AUTOSAR XML (schema 4-0-3)
package /ComponentTypes
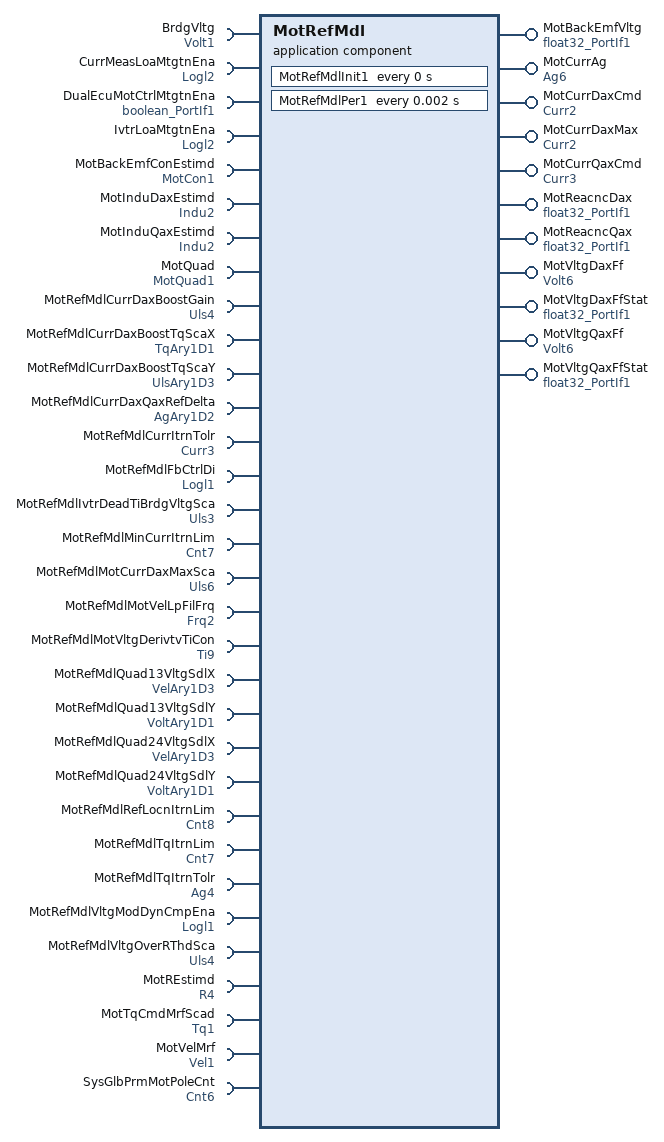
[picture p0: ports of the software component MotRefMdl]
  application sw component type MotRefMdl
    11 x provide port, all with nonqueued-sender-com-spec{data-element=Val, init-value=0}:
      MotBackEmfVltg: provided-interface=float32_PortIf1
      MotCurrAg: provided-interface=Ag6
      MotCurrDaxCmd: provided-interface=Curr2
      MotCurrDaxMax: provided-interface=Curr2
      MotCurrQaxCmd: provided-interface=Curr3
      MotReacncDax: provided-interface=float32_PortIf1
      MotReacncQax: provided-interface=float32_PortIf1
      MotVltgDaxFf: provided-interface=Volt6
      MotVltgDaxFfStat: provided-interface=float32_PortIf1
      MotVltgQaxFf: provided-interface=Volt6
      MotVltgQaxFfStat: provided-interface=float32_PortIf1
    32 x require port:
      BrdgVltg: nonqueued-receiver-com-spec{data-element=Val, filter=data-filter-type=ALWAYS, init-value=6}, required-interface=Volt1
      CurrMeasLoaMtgtnEna: nonqueued-receiver-com-spec{data-element=Logl, filter=data-filter-type=ALWAYS, init-value=0}, required-interface=Logl2
      DualEcuMotCtrlMtgtnEna: nonqueued-receiver-com-spec{data-element=Logl, filter=data-filter-type=ALWAYS, init-value=0}, required-interface=boolean_PortIf1
      IvtrLoaMtgtnEna: nonqueued-receiver-com-spec{data-element=Logl, filter=data-filter-type=ALWAYS, init-value=0}, required-interface=Logl2
      MotBackEmfConEstimd: nonqueued-receiver-com-spec{data-element=Val, filter=data-filter-type=ALWAYS, init-value=0.025}, required-interface=MotCon1
      MotInduDaxEstimd: nonqueued-receiver-com-spec{data-element=Val, filter=data-filter-type=ALWAYS, init-value=0.00011889}, required-interface=Indu2
      MotInduQaxEstimd: nonqueued-receiver-com-spec{data-element=Val, filter=data-filter-type=ALWAYS, init-value=0.00011889}, required-interface=Indu2
      MotQuad: nonqueued-receiver-com-spec{data-element=Val, filter=data-filter-type=ALWAYS, init-value=1}, required-interface=MotQuad1
      MotRefMdlCurrDaxBoostGain: parameter-require-com-spec{init-value=0, parameter=Val}, required-interface=Uls4
      MotRefMdlCurrDaxBoostTqScaX: parameter-require-com-spec{init-value=[0, 1.5, 1.75, 2, 2.25, 2.5, 3, 3.5, 4, 4.5, 5], parameter=Ary1D}, required-interface=TqAry1D1
      MotRefMdlCurrDaxBoostTqScaY: parameter-require-com-spec{init-value=[0, 0.5, 0.6, 0.7, 0.725, 0.775, 0.825, 0.85, 0.9, 0.95, 1], parameter=Ary1D}, required-interface=UlsAry1D3
      MotRefMdlCurrDaxQaxRefDelta: parameter-require-com-spec{init-value=[-3.1415927, -2.3561945, -1.5707964, -0.7853982, 0, 0.7853982, 1.5707964, 2.3561945], parameter=Ary1D}, required-interface=AgAry1D2
      MotRefMdlCurrItrnTolr: parameter-require-com-spec{init-value=0.1, parameter=Val}, required-interface=Curr3
      MotRefMdlFbCtrlDi: parameter-require-com-spec{init-value=0, parameter=Logl}, required-interface=Logl1
      MotRefMdlIvtrDeadTiBrdgVltgSca: parameter-require-com-spec{init-value=1, parameter=Val}, required-interface=Uls3
      MotRefMdlMinCurrItrnLim: parameter-require-com-spec{init-value=3, parameter=Val}, required-interface=Cnt7
      MotRefMdlMotCurrDaxMaxSca: parameter-require-com-spec{init-value=1, parameter=Val}, required-interface=Uls6
      MotRefMdlMotVelLpFilFrq: parameter-require-com-spec{init-value=125, parameter=Val}, required-interface=Frq2
      MotRefMdlMotVltgDerivtvTiCon: parameter-require-com-spec{init-value=0.0026526, parameter=Val}, required-interface=Ti9
      MotRefMdlQuad13VltgSdlX: parameter-require-com-spec{init-value=[0, 100, 200, 300, 500, 600, 700, 800, 900, 1100], parameter=Ary1D}, required-interface=VelAry1D3
      MotRefMdlQuad13VltgSdlY: parameter-require-com-spec{init-value=10 x 0, parameter=Ary1D}, required-interface=VoltAry1D1
      MotRefMdlQuad24VltgSdlX: parameter-require-com-spec{init-value=[0, 100, 200, 300, 500, 600, 700, 800, 900, 1100], parameter=Ary1D}, required-interface=VelAry1D3
      MotRefMdlQuad24VltgSdlY: parameter-require-com-spec{init-value=10 x 0, parameter=Ary1D}, required-interface=VoltAry1D1
      MotRefMdlRefLocnItrnLim: parameter-require-com-spec{init-value=10, parameter=Val}, required-interface=Cnt8
      MotRefMdlTqItrnLim: parameter-require-com-spec{init-value=3, parameter=Val}, required-interface=Cnt7
      MotRefMdlTqItrnTolr: parameter-require-com-spec{init-value=0.015, parameter=Val}, required-interface=Ag4
      MotRefMdlVltgModDynCmpEna: parameter-require-com-spec{init-value=0, parameter=Logl}, required-interface=Logl1
      MotRefMdlVltgOverRThdSca: parameter-require-com-spec{init-value=.25, parameter=Val}, required-interface=Uls4
      MotREstimd: nonqueued-receiver-com-spec{data-element=Val, filter=data-filter-type=ALWAYS, init-value=0.005}, required-interface=R4
      MotTqCmdMrfScad: nonqueued-receiver-com-spec{data-element=Val, filter=data-filter-type=ALWAYS, init-value=0}, required-interface=Tq1
      MotVelMrf: nonqueued-receiver-com-spec{data-element=Val, filter=data-filter-type=ALWAYS, init-value=0}, required-interface=Vel1
      SysGlbPrmMotPoleCnt: parameter-require-com-spec{init-value=6, parameter=Val}, required-interface=Cnt6
    behavior MotRefMdl_InternalBehavior: data-type-mapping=Nexteer
      ar-typed-per-instance-memorys:
        28 x data, all with sw-calibration-access=READ-ONLY:
          CosDelta: type=UlsAry1D6
          dMotRefMdlCurrDaxAtPeakTq: type=Curr6
          dMotRefMdlCurrDaxMin: type=Curr6
          dMotRefMdlCurrQaxMin: type=Curr7
          dMotRefMdlCurrSqdMin: type=CurrSqd1
          dMotRefMdlInterCalcnCurrDaxMax: type=Curr6
          dMotRefMdlMinCurrNrItrn: type=Cnt19
          dMotRefMdlMotCurrDaxBoost: type=Curr6
          dMotRefMdlMotTqCmdLimd: type=Tq1
          dMotRefMdlMotVelFildFf: type=Vel1
          dMotRefMdlMotVltgDaxFfDyn: type=Volt17
          dMotRefMdlMotVltgDaxFfDynTerm: type=Volt17
          dMotRefMdlMotVltgDaxFfStat: type=float32
          dMotRefMdlMotVltgQaxFfDyn: type=Volt17
          dMotRefMdlMotVltgQaxFfDynTerm: type=Volt17
          dMotRefMdlMotVltgQaxFfStat: type=float32
          dMotRefMdlPeakTq: type=Tq1
          dMotRefMdlPeakTqNrItrn: type=Cnt19
          dMotRefMdlPhaAdvAtPeakTq: type=Ag10
          dMotRefMdlReacncDaxOverR: type=Uls13
          dMotRefMdlReacncQaxOverR: type=Uls13
          dMotRefMdlRelncTqCoeff: type=Indu2
          MotCurrDaxCmdPrev: type=Curr6
          MotCurrQaxCmdPrev: type=Curr7
          MotVelLpFil: type=FilLpRec1
          SinDelta: type=UlsAry1D6
          VltgDaxFfTermPrev: type=Volt17
          VltgQaxFfTermPrev: type=Volt17
      timing event MotRefMdlInit1_InitEvent: start-on-event=MotRefMdlInit1, period=0
      timing event TMT_MotRefMdlPer1: start-on-event=MotRefMdlPer1, period=0.002
      runnable MotRefMdlInit1
      runnable MotRefMdlPer1
        data-receive-point-by-arguments:
          11 x access:
            REC_BrdgVltg_Val: accessed-variable=BrdgVltg.Val
            REC_DualEcuMotCtrlMtgtnEna_Logl: accessed-variable=DualEcuMotCtrlMtgtnEna.Logl
            REC_IvtrLoaMtgtnEna_Logl: accessed-variable=IvtrLoaMtgtnEna.Logl
            REC_MotBackEmfConEstimd_Val: accessed-variable=MotBackEmfConEstimd.Val
            REC_MotCurrLoaMtgtnEna_Logl: accessed-variable=CurrMeasLoaMtgtnEna.Logl
            REC_MotInduDaxEstimd_Val: accessed-variable=MotInduDaxEstimd.Val
            REC_MotInduQaxEstimd_Val: accessed-variable=MotInduQaxEstimd.Val
            REC_MotQuad_Val: accessed-variable=MotQuad.Val
            REC_MotREstimd_Val: accessed-variable=MotREstimd.Val
            REC_MotTqCmdMrfScad_Val: accessed-variable=MotTqCmdMrfScad.Val
            REC_MotVelMrf_Val: accessed-variable=MotVelMrf.Val
        data-send-points:
          11 x access:
            SEND_MotCtrlMotBackEmfVltg_Val: accessed-variable=MotBackEmfVltg.Val
            SEND_MotCurrAg_Val: accessed-variable=MotCurrAg.Val
            SEND_MotCurrDaxCmd_Val: accessed-variable=MotCurrDaxCmd.Val
            SEND_MotCurrDaxMax_Val: accessed-variable=MotCurrDaxMax.Val
            SEND_MotCurrQaxCmd_Val: accessed-variable=MotCurrQaxCmd.Val
            SEND_MotReacncDax_Val_1: accessed-variable=MotReacncDax.Val
            SEND_MotReacncQax_Val_1: accessed-variable=MotReacncQax.Val
            SEND_MotVltgDaxFf_Val: accessed-variable=MotVltgDaxFf.Val
            SEND_MotVltgDaxFfStat_Val: accessed-variable=MotVltgDaxFfStat.Val
            SEND_MotVltgQaxFf_Val: accessed-variable=MotVltgQaxFf.Val
            SEND_MotVltgQaxFfStat_Val: accessed-variable=MotVltgQaxFfStat.Val
  swc implementation MotRefMdl_Implementation: behavior=MotRefMdl_InternalBehavior
    code-descriptors:
      code Default: artifact-descriptors=autosar-engineering-object={short-label=Default, category=SWSRC}
